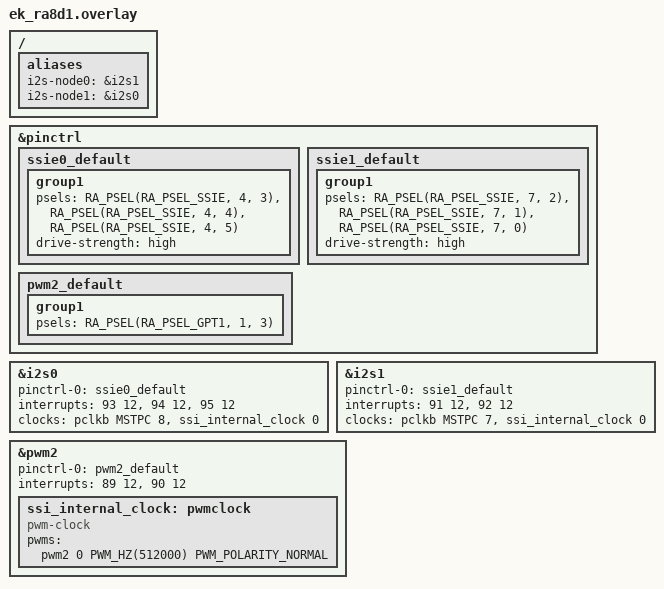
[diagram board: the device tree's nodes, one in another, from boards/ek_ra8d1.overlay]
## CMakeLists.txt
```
# SPDX-License-Identifier: Apache-2.0

cmake_minimum_required(VERSION 3.28.0)

find_package(Zephyr REQUIRED HINTS $ENV{ZEPHYR_BASE})
project(i2s_api)

FILE(GLOB app_sources src/*.c)
list(FILTER app_sources EXCLUDE REGEX "test_i2s_pm\\.c$")
target_sources(app PRIVATE ${app_sources})
target_sources_ifdef(CONFIG_PM app PRIVATE src/test_i2s_pm.c)
```

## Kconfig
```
#
# Copyright (c) 2021, NXP
#
# SPDX-License-Identifier: Apache-2.0
#

mainmenu "I2S Loopback Test"

source "Kconfig.zephyr"

config I2S_TEST_SEPARATE_DEVICES
	bool "Use two separate I2S ports for loopback"
	help
	  Use separate I2S ports for transmit and receive.

config I2S_TEST_USE_I2S_DIR_BOTH
	bool "Use I2S_DIR_BOTH value to perform RX/TX transfers"
	default y if DT_HAS_NORDIC_NRF_I2S_ENABLED || DT_HAS_NORDIC_NRF_TDM_ENABLED
	help
	  Use the I2S_DIR_BOTH enumeration value to trigger commands in test
	  cases involving both reception and transmission. Use of this option
	  is essential for devices that cannot independently start and stop
	  the RX and TX streams.

config I2S_TEST_USE_GPIO_LOOPBACK
	bool "Use GPIO loopback"
	default y if DT_HAS_NORDIC_NRF_I2S_ENABLED || DT_HAS_NORDIC_NRF_TDM_ENABLED
	help
	  Use wiring between the data-out and data-in pins for looping back
	  data. This option is intended to be used for devices that do not
	  provide the internal loopback functionality.

config I2S_TEST_ALLOWED_DATA_OFFSET
	int "Allowed offset in received data"
	default 2 if DT_HAS_NORDIC_NRF_I2S_ENABLED || DT_HAS_NORDIC_NRF_TDM_ENABLED
	default 0
	help
	  Maximum allowed offset between sent and received samples. Non-zero
	  value of this option may be needed when GPIO loopback is used.

config I2S_TEST_ALLOW_VARIABLE_OFFSET
	bool "Recalculate the data offset on every block read"
	help
	  If the data offset is not consistent between reads because of
	  timing variations in the hardware, enable this option to
	  always recalculate the offset.
```

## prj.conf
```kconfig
CONFIG_I2S=y
CONFIG_ZTEST=y
CONFIG_TEST_USERSPACE=y
# The tdm_channel_masking test suite may be skipped
CONFIG_ZTEST_VERIFY_RUN_ALL=n
```

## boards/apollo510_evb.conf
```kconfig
# Copyright (c) 2026 Ambiq Micro Inc.
# SPDX-License-Identifier: Apache-2.0

CONFIG_I2S_TEST_USE_GPIO_LOOPBACK=y
CONFIG_I2S_TEST_USE_I2S_DIR_BOTH=y
CONFIG_I2S_TEST_ALLOWED_DATA_OFFSET=2
```

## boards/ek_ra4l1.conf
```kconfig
# Copyright (c) 2025 Renesas Electronics Corporation
# SPDX-License-Identifier: Apache-2.0

CONFIG_I2S_INIT_PRIORITY=52
CONFIG_I2S_TEST_USE_GPIO_LOOPBACK=y
CONFIG_I2S_TEST_USE_I2S_DIR_BOTH=y
```

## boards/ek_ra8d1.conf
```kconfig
# Copyright (c) 2025 Renesas Electronics Corporation
# SPDX-License-Identifier: Apache-2.0

CONFIG_I2S_INIT_PRIORITY=52
CONFIG_I2S_TEST_USE_GPIO_LOOPBACK=y
CONFIG_I2S_TEST_SEPARATE_DEVICES=y
```

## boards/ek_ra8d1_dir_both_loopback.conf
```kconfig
#
# Copyright (c) 2025 Renesas Electronics Corporation
#
# SPDX-License-Identifier: Apache-2.0
#

CONFIG_PWM=y
CONFIG_CLOCK_CONTROL=y
CONFIG_I2S_INIT_PRIORITY=52
CONFIG_I2S_TEST_USE_GPIO_LOOPBACK=y
CONFIG_I2S_TEST_USE_I2S_DIR_BOTH=y
CONFIG_CLOCK_CONTROL_FIXED_RATE_CLOCK=y
```

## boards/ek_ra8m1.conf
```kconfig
#
# Copyright (c) 2025 Renesas Electronics Corporation
#
# SPDX-License-Identifier: Apache-2.0
#

CONFIG_PWM=y
CONFIG_CLOCK_CONTROL=y
CONFIG_I2S_INIT_PRIORITY=52
CONFIG_I2S_TEST_USE_GPIO_LOOPBACK=y
CONFIG_I2S_TEST_SEPARATE_DEVICES=y
CONFIG_CLOCK_CONTROL_FIXED_RATE_CLOCK=y
```

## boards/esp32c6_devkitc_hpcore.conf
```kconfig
# Copyright (c) 2025 Espressif Systems (Shanghai) Co., Ltd.
# SPDX-License-Identifier: Apache-2.0

CONFIG_I2S_TEST_USE_GPIO_LOOPBACK=y
CONFIG_I2S_TEST_ALLOWED_DATA_OFFSET=1
```

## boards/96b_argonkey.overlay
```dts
test_i2s_rx: &i2s5 {};

test_i2s_tx: &i2s5 {};
```

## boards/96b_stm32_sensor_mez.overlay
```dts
/*
 * SPDX-FileCopyrightText: Copyright The Zephyr Project Contributors
 * SPDX-License-Identifier: Apache-2.0
 */

/* i2s-node0 is the transmitter/receiver */

/ {
	aliases {
		i2s-node0 = &i2s2;
	};
};
```

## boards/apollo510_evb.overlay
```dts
/*
 * Copyright (c) 2026 Ambiq Micro Inc.
 *
 * SPDX-License-Identifier: Apache-2.0
 */

/*
 * GPIO loopback: wire I2S0_SDOUT (P6) to I2S0_SDIN (P4).
 * CLK is P5, WS is P7.
 */

/ {
	aliases {
		i2s-node0 = &i2s0;
	};
};

&i2s0 {
	status = "okay";
};
```

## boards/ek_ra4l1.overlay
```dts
/*
 * Copyright (c) 2025 Renesas Electronics Corporation
 *
 * SPDX-License-Identifier: Apache-2.0
 */

#include <zephyr/dt-bindings/pwm/pwm.h>

/ {
	aliases {
		i2s-node0 = &i2s0;
	};
};

&pinctrl {
	ssie0_default: ssie0_default {
		group1 {
			/* SSI_BCK SSI_LRCK SSI_TX SSI_RX */
			psels = <RA_PSEL(RA_PSEL_SSIE, 4, 3)>,
				<RA_PSEL(RA_PSEL_SSIE, 4, 4)>,
				<RA_PSEL(RA_PSEL_SSIE, 6, 8)>,
				<RA_PSEL(RA_PSEL_SSIE, 1, 15)>;
			drive-strength = "high";
		};
	};

	pwm2_default: pwm2_default {
		group1 {
			/* GTIOC2A */
			psels = <RA_PSEL(RA_PSEL_GPT1, 4, 7)>;
		};
	};
};

&i2s0 {
	pinctrl-0 = <&ssie0_default>;
	pinctrl-names = "default";
	interrupts = <61 12>, <62 12>, <63 12>;
	interrupt-names = "ssi_txi", "ssi_rxi", "ssi_if";
	clocks = <&pclkb MSTPC 8>, <&ssi_internal_clock 0>;
	clock-names = "pclk", "audio-clock";
	status = "okay";
};

&pwm2 {
	pinctrl-0 = <&pwm2_default>;
	pinctrl-names = "default";
	interrupts = <59 12>, <60 12>;
	interrupt-names = "gtioca", "overflow";
	status = "okay";

	ssi_internal_clock: pwmclock {
		compatible = "pwm-clock";
		#clock-cells = <1>;
		pwms = <&pwm2 0 PWM_HZ(512000) PWM_POLARITY_NORMAL>;
		status = "okay";
	};
};
```

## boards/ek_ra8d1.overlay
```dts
/*
 * Copyright (c) 2025 Renesas Electronics Corporation
 *
 * SPDX-License-Identifier: Apache-2.0
 */

#include <zephyr/dt-bindings/pwm/pwm.h>

/ {
	aliases {
		i2s-node0 = &i2s1;
		i2s-node1 = &i2s0;
	};
};

&pinctrl {
	ssie0_default: ssie0_default {
		group1 {
			/* SSI_BCK SSI_LRCK SSI_TX */
			psels = <RA_PSEL(RA_PSEL_SSIE, 4, 3)>,
				<RA_PSEL(RA_PSEL_SSIE, 4, 4)>,
				<RA_PSEL(RA_PSEL_SSIE, 4, 5)>;
			drive-strength = "high";
		};
	};

	ssie1_default: ssie1_default {
		group1 {
			/* SSI_BCK SSI_LRCK SSI_DATA */
			psels = <RA_PSEL(RA_PSEL_SSIE, 7, 2)>,
				<RA_PSEL(RA_PSEL_SSIE, 7, 1)>,
				<RA_PSEL(RA_PSEL_SSIE, 7, 0)>;
			drive-strength = "high";
		};
	};

	pwm2_default: pwm2_default {
		group1 {
			/* GTIOC2A */
			psels = <RA_PSEL(RA_PSEL_GPT1, 1, 3)>;
		};
	};
};

&i2s0 {
	pinctrl-0 = <&ssie0_default>;
	pinctrl-names = "default";
	interrupts = <93 12>, <94 12>, <95 12>;
	interrupt-names = "ssi_txi", "ssi_rxi", "ssi_if";
	clocks = <&pclkb MSTPC 8>, <&ssi_internal_clock 0>;
	clock-names = "pclk", "audio-clock";
	status = "okay";
};

&i2s1 {
	pinctrl-0 = <&ssie1_default>;
	pinctrl-names = "default";
	interrupts = <91 12>, <92 12>;
	interrupt-names = "ssi_rt", "ssi_if";
	clocks = <&pclkb MSTPC 7>, <&ssi_internal_clock 0>;
	clock-names = "pclk", "audio-clock";
	status = "okay";
};

&pwm2 {
	pinctrl-0 = <&pwm2_default>;
	pinctrl-names = "default";
	interrupts = <89 12>, <90 12>;
	interrupt-names = "gtioca", "overflow";
	status = "okay";

	ssi_internal_clock: pwmclock {
		compatible = "pwm-clock";
		#clock-cells = <1>;
		pwms = <&pwm2 0 PWM_HZ(512000) PWM_POLARITY_NORMAL>;
		status = "okay";
	};
};
```

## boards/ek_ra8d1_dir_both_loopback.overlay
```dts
/*
 * Copyright (c) 2025 Renesas Electronics Corporation
 *
 * SPDX-License-Identifier: Apache-2.0
 */

#include <zephyr/dt-bindings/pwm/pwm.h>

/ {
	aliases {
		i2s-node0 = &i2s0;
	};
};

&pinctrl {
	ssie0_default: ssie0_default {
		group1 {
			/* SSI_BCK SSI_LRCK SSI_TX SSI_RX */
			psels = <RA_PSEL(RA_PSEL_SSIE, 4, 3)>,
				<RA_PSEL(RA_PSEL_SSIE, 4, 4)>,
				<RA_PSEL(RA_PSEL_SSIE, 4, 5)>,
				<RA_PSEL(RA_PSEL_SSIE, 4, 6)>;
			drive-strength = "high";
		};
	};

	pwm2_default: pwm2_default {
		group1 {
			/* GTIOC2A */
			psels = <RA_PSEL(RA_PSEL_GPT1, 1, 3)>;
		};
	};
};

&i2s0 {
	pinctrl-0 = <&ssie0_default>;
	pinctrl-names = "default";
	interrupts = <93 12>, <94 12>, <95 12>;
	interrupt-names = "ssi_txi", "ssi_rxi", "ssi_if";
	clocks = <&pclkb MSTPC 8>, <&ssi_internal_clock 0>;
	clock-names = "pclk", "audio-clock";
	status = "okay";
};

&pwm2 {
	pinctrl-0 = <&pwm2_default>;
	pinctrl-names = "default";
	interrupts = <91 12>, <92 12>;
	interrupt-names = "gtioca", "overflow";
	status = "okay";

	ssi_internal_clock: pwmclock {
		compatible = "pwm-clock";
		#clock-cells = <1>;
		pwms = <&pwm2 0 PWM_HZ(512000) PWM_POLARITY_NORMAL>;
		status = "okay";
	};
};
```

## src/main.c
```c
/*
 * Copyright (c) 2017 comsuisse AG
 *
 * SPDX-License-Identifier: Apache-2.0
 */


#include <zephyr/kernel.h>
#include <zephyr/ztest.h>
#include <zephyr/device.h>
#include "i2s_api_test.h"

ZTEST_DMEM const struct device *dev_i2s_rx =
	DEVICE_DT_GET_OR_NULL(I2S_DEV_NODE_RX);
ZTEST_DMEM const struct device *dev_i2s_tx =
	DEVICE_DT_GET_OR_NULL(I2S_DEV_NODE_TX);
ZTEST_DMEM const struct device *dev_i2s =
	DEVICE_DT_GET_OR_NULL(I2S_DEV_NODE_RX);
ZTEST_DMEM bool dir_both_supported;

static void *setup(void)
{
	k_thread_access_grant(k_current_get(),
			      &rx_mem_slab, &tx_mem_slab);
	k_object_access_grant(dev_i2s_rx, k_current_get());
	k_object_access_grant(dev_i2s_tx, k_current_get());

	return NULL;
}

static void before(void *fixture)
{
	ARG_UNUSED(fixture);

	int ret;

	zassert_not_null(dev_i2s_rx, "RX device not found");
	zassert_true(device_is_ready(dev_i2s_rx),
		     "device %s is not ready", dev_i2s_rx->name);
	zassert_not_null(dev_i2s_tx, "TX device not found");
	zassert_true(device_is_ready(dev_i2s_tx),
		     "device %s is not ready", dev_i2s_tx->name);

	ret = configure_stream(dev_i2s_rx, I2S_DIR_RX);
	zassert_equal(ret, TC_PASS);

	ret = configure_stream(dev_i2s_tx, I2S_DIR_TX);
	zassert_equal(ret, TC_PASS);
}

static void before_dir_both(void *fixture)
{
	ARG_UNUSED(fixture);

	int ret;

	zassert_not_null(dev_i2s, "TX/RX device not found");
	zassert_true(device_is_ready(dev_i2s),
		     "device %s is not ready", dev_i2s->name);

	ret = configure_stream(dev_i2s, I2S_DIR_BOTH);
	zassert_equal(ret, TC_PASS);

	/* Check if the tested driver supports the I2S_DIR_BOTH value.
	 * Use the DROP trigger for this, as in the current state of the driver
	 * (READY, both TX and RX queues empty) it is actually a no-op.
	 */
	ret = i2s_trigger(dev_i2s, I2S_DIR_BOTH, I2S_TRIGGER_DROP);
	dir_both_supported = (ret == 0);

	if (IS_ENABLED(CONFIG_I2S_TEST_USE_I2S_DIR_BOTH)) {
		zassert_true(dir_both_supported,
			     "I2S_DIR_BOTH value is supposed to be supported.");
	}
}

ZTEST_SUITE(i2s_loopback, NULL, setup, before, NULL, NULL);
ZTEST_SUITE(i2s_states, NULL, setup, before, NULL, NULL);
ZTEST_SUITE(i2s_dir_both_states, NULL, setup, before_dir_both, NULL, NULL);
ZTEST_SUITE(i2s_dir_both_loopback, NULL, setup, before_dir_both, NULL, NULL);
ZTEST_SUITE(i2s_errors, NULL, setup, before, NULL, NULL);
ZTEST_SUITE(tdm_channel_masking, tdm_channel_masking_supported, setup, before_dir_both, NULL, NULL);
```

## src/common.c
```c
/*
 * Copyright (c) 2017 comsuisse AG
 *
 * SPDX-License-Identifier: Apache-2.0
 */

#include <zephyr/kernel.h>
#include <zephyr/ztest.h>
#include <zephyr/drivers/i2s.h>
#include "i2s_api_test.h"

/* Cache-line align the blocks so cache maintenance on one block cannot
 * corrupt a neighbouring block
 */
#ifdef CONFIG_DCACHE_LINE_SIZE
#define SLAB_ALIGN MAX(32, CONFIG_DCACHE_LINE_SIZE)
#else
#define SLAB_ALIGN 32
#endif

K_MEM_SLAB_DEFINE(rx_mem_slab, BLOCK_SIZE, NUM_RX_BLOCKS, SLAB_ALIGN);
K_MEM_SLAB_DEFINE(tx_mem_slab, BLOCK_SIZE, NUM_TX_BLOCKS, SLAB_ALIGN);

/* The data_l represent a sine wave */
ZTEST_DMEM int16_t data_l[SAMPLE_NO] = {
	  6392,  12539,  18204,  23169,  27244,  30272,  32137,  32767,  32137,
	 30272,  27244,  23169,  18204,  12539,   6392,      0,  -6393, -12540,
	-18205, -23170, -27245, -30273, -32138, -32767, -32138, -30273, -27245,
	-23170, -18205, -12540,  -6393,     -1,
};

/* The data_r represent a sine wave with double the frequency of data_l */
ZTEST_DMEM int16_t data_r[SAMPLE_NO] = {
	 12539,  23169,  30272,  32767,  30272,  23169,  12539,      0, -12540,
	-23170, -30273, -32767, -30273, -23170, -12540,     -1,  12539,  23169,
	 30272,  32767,  30272,  23169,  12539,      0, -12540, -23170, -30273,
	-32767, -30273, -23170, -12540,     -1,
};

static void fill_buf(int16_t *tx_block, int att)
{
	for (int i = 0; i < SAMPLE_NO; i++) {
		tx_block[2 * i] = data_l[i] >> att;
		tx_block[2 * i + 1] = data_r[i] >> att;
	}
}

static int verify_buf(int16_t *rx_block, int att)
{
	int sample_no = SAMPLE_NO;

#if (CONFIG_I2S_TEST_ALLOWED_DATA_OFFSET > 0)
#if (CONFIG_I2S_TEST_ALLOW_VARIABLE_OFFSET)
	int offset = -1;
#else
	static ZTEST_DMEM int offset = -1;
#endif

	if (offset < 0) {
		do {
			++offset;
			if (offset > CONFIG_I2S_TEST_ALLOWED_DATA_OFFSET) {
				TC_PRINT("Allowed data offset exceeded\n");
				return -TC_FAIL;
			}
		} while (rx_block[2 * offset] != data_l[0] >> att);

#if (!CONFIG_I2S_TEST_ALLOW_VARIABLE_OFFSET)
		TC_PRINT("Using data offset: %d\n", offset);
#endif
	}

	rx_block += 2 * offset;
	sample_no -= offset;
#endif

	for (int i = 0; i < sample_no; i++) {
		if (rx_block[2 * i] != data_l[i] >> att) {
			TC_PRINT("Error: att %d: data_l mismatch at position "
				 "%d, expected %d, actual %d\n",
				 att, i, data_l[i] >> att, rx_block[2 * i]);
			return -TC_FAIL;
		}
		if (rx_block[2 * i + 1] != data_r[i] >> att) {
			TC_PRINT("Error: att %d: data_r mismatch at position "
				 "%d, expected %d, actual %d\n",
				 att, i, data_r[i] >> att, rx_block[2 * i + 1]);
			return -TC_FAIL;
		}
	}

	return TC_PASS;
}

void fill_buf_const(int16_t *tx_block, int16_t val_l, int16_t val_r)
{
	for (int i = 0; i < SAMPLE_NO; i++) {
		tx_block[2 * i] = val_l;
		tx_block[2 * i + 1] = val_r;
	}
}

int verify_buf_const(int16_t *rx_block, int16_t val_l, int16_t val_r)
{
	int sample_no = SAMPLE_NO;

#if (CONFIG_I2S_TEST_ALLOWED_DATA_OFFSET > 0)
	static ZTEST_DMEM int offset = -1;

	if (offset < 0) {
		do {
			++offset;
			if (offset > CONFIG_I2S_TEST_ALLOWED_DATA_OFFSET) {
				TC_PRINT("Allowed data offset exceeded\n");
				return -TC_FAIL;
			}
		} while (rx_block[2 * offset] != val_l);
	}

	rx_block += 2 * offset;
	sample_no -= offset;
#endif

	for (int i = 0; i < sample_no; i++) {
		if (rx_block[2 * i] != val_l) {
			TC_PRINT("Error: data_l mismatch at position "
				 "%d, expected %d, actual %d\n",
				 i, val_l, rx_block[2 * i]);
			return -TC_FAIL;
		}
		if (rx_block[2 * i + 1] != val_r) {
			TC_PRINT("Error: data_r mismatch at position "
				 "%d, expected %d, actual %d\n",
				 i, val_r, rx_block[2 * i + 1]);
			return -TC_FAIL;
		}
	}

	return TC_PASS;
}

static int tx_block_write_slab(const struct device *dev_i2s, int att, int err,
			       struct k_mem_slab *slab)
{
	char tx_block[BLOCK_SIZE];
	int ret;

	fill_buf((uint16_t *)tx_block, att);
	ret = i2s_buf_write(dev_i2s, tx_block, BLOCK_SIZE);
	if (ret != err) {
		TC_PRINT("Error: i2s_write failed expected %d, actual %d\n",
			 err, ret);
		return -TC_FAIL;
	}

	return TC_PASS;
}

int tx_block_write(const struct device *dev_i2s, int att, int err)
{
	return tx_block_write_slab(dev_i2s, att, err, &tx_mem_slab);
}

static int rx_block_read_slab(const struct device *dev_i2s, int att,
			      struct k_mem_slab *slab)
{
	char rx_block[BLOCK_SIZE];
	size_t rx_size;
	int ret;

	ret = i2s_buf_read(dev_i2s, rx_block, &rx_size);
	if (ret < 0 || rx_size != BLOCK_SIZE) {
		TC_PRINT("Error: Read failed\n");
		return -TC_FAIL;
	}
	ret = verify_buf((uint16_t *)rx_block, att);
	if (ret < 0) {
		TC_PRINT("Error: Verify failed\n");
		return -TC_FAIL;
	}

	return TC_PASS;
}

int rx_block_read(const struct device *dev_i2s, int att)
{
	return rx_block_read_slab(dev_i2s, att, &rx_mem_slab);
}

int configure_stream(const struct device *dev_i2s, enum i2s_dir dir)
{
	int ret;
	struct i2s_config i2s_cfg = {0};

	i2s_cfg.word_size = 16U;
	i2s_cfg.channels = 2U;
	i2s_cfg.format = I2S_FMT_DATA_FORMAT_I2S;
	i2s_cfg.frame_clk_freq = FRAME_CLK_FREQ;
	i2s_cfg.block_size = BLOCK_SIZE;
	i2s_cfg.timeout = TIMEOUT;

	if (dir == I2S_DIR_TX) {
		/* Configure the Transmit port as Controller */
		i2s_cfg.options = I2S_OPT_FRAME_CLK_CONTROLLER
				| I2S_OPT_BIT_CLK_CONTROLLER;
	} else if (dir == I2S_DIR_RX) {
		/* Configure the Receive port as Target */
		i2s_cfg.options = I2S_OPT_FRAME_CLK_TARGET
				| I2S_OPT_BIT_CLK_TARGET;
	} else { /* dir == I2S_DIR_BOTH */
		i2s_cfg.options = I2S_OPT_FRAME_CLK_CONTROLLER
				| I2S_OPT_BIT_CLK_CONTROLLER;
	}

	if (!IS_ENABLED(CONFIG_I2S_TEST_USE_GPIO_LOOPBACK)) {
		i2s_cfg.options |= I2S_OPT_LOOPBACK;
	}

	if (dir == I2S_DIR_TX || dir == I2S_DIR_BOTH) {
		i2s_cfg.mem_slab = &tx_mem_slab;
		ret = i2s_configure(dev_i2s, I2S_DIR_TX, &i2s_cfg);
		if (ret < 0) {
			TC_PRINT("Failed to configure I2S TX stream (%d)\n",
				 ret);
			return -TC_FAIL;
		}
	}

	if (dir == I2S_DIR_RX || dir == I2S_DIR_BOTH) {
		i2s_cfg.mem_slab = &rx_mem_slab;
		ret = i2s_configure(dev_i2s, I2S_DIR_RX, &i2s_cfg);
		if (ret < 0) {
			TC_PRINT("Failed to configure I2S RX stream (%d)\n",
				 ret);
			return -TC_FAIL;
		}
	}

	return TC_PASS;
}

int i2s_check_state(const struct device *dev_i2s, enum i2s_dir dir, enum i2s_state expected_state,
		    k_timeout_t timeout)
{
	k_timepoint_t end = sys_timepoint_calc(timeout);
	enum i2s_state state;

	do {
		state = i2s_get_state(dev_i2s, dir);

		if (state == expected_state) {
			return TC_PASS;
		}

		if ((state == I2S_STATE_UNKNOWN) && !I2S_TEST_STATE_REQUIRED) {
			TC_PRINT("State check skipped: driver does not report state for dir %d\n",
				 dir);
			return TC_PASS;
		}

		if (state != I2S_STATE_STOPPING) {
			break;
		}

		k_sleep(K_MSEC(1));
	} while (!sys_timepoint_expired(end));

	TC_PRINT("Unexpected state for dir %d: got %d, expected %d\n", dir, state, expected_state);

	return -TC_FAIL;
}
```

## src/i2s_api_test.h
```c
/*
 * Copyright (c) 2017 comsuisse AG
 * Copyright (c) 2018 Intel Corporation
 *
 * SPDX-License-Identifier: Apache-2.0
 */

#ifndef I2S_API_TEST_H
#define I2S_API_TEST_H

#include <zephyr/kernel.h>
#include <zephyr/drivers/i2s.h>

extern struct k_mem_slab rx_mem_slab;
extern struct k_mem_slab tx_mem_slab;

#define SAMPLE_NO	32
#define TIMEOUT		2000
#define FRAME_CLK_FREQ	8000

extern int16_t data_l[SAMPLE_NO];
extern int16_t data_r[SAMPLE_NO];

extern const struct device *dev_i2s_rx;
extern const struct device *dev_i2s_tx;
extern const struct device *dev_i2s;
extern bool dir_both_supported;

#define I2S_DEV_NODE_RX DT_ALIAS(i2s_node0)
#ifdef CONFIG_I2S_TEST_SEPARATE_DEVICES
#define I2S_DEV_NODE_TX DT_ALIAS(i2s_node1)
#else
#define I2S_DEV_NODE_TX DT_ALIAS(i2s_node0)
#endif
#define BLOCK_SIZE (2 * sizeof(data_l))

#define NUM_RX_BLOCKS	4
#define NUM_TX_BLOCKS	4

#define I2S_STATE_TIMEOUT K_MSEC(50)

/* Drivers known to implement i2s_get_state(). For these, I2S_STATE_UNKNOWN is
 * a test failure instead of a skipped check.
 */
#define I2S_TEST_STATE_REQUIRED DT_HAS_COMPAT_STATUS_OKAY(zephyr_native_sim_i2s)

int tx_block_write(const struct device *dev_i2s, int att, int err);
int rx_block_read(const struct device *dev_i2s, int att);

void fill_buf_const(int16_t *tx_block, int16_t val_l, int16_t val_r);
int verify_buf_const(int16_t *rx_block, int16_t val_l, int16_t val_r);

int configure_stream(const struct device *dev_i2s, enum i2s_dir dir);

int i2s_check_state(const struct device *dev_i2s, enum i2s_dir dir, enum i2s_state expected_state,
		    k_timeout_t timeout);

#endif
```

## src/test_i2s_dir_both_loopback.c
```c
/*
 * Copyright (c) 2017 comsuisse AG
 * Copyright (c) 2021 Nordic Semiconductor ASA
 *
 * SPDX-License-Identifier: Apache-2.0
 */

#include <zephyr/kernel.h>
#include <zephyr/ztest.h>
#include <zephyr/drivers/i2s.h>
#include "i2s_api_test.h"

/* The test cases here are copied from test_i2s_loopback.c and adapted for use
 * on devices that cannot independently start and stop the RX and TX streams
 * and require the use of the I2S_DIR_BOTH value for RX/TX transfers.
 */

/** @brief Short I2S transfer.
 *
 * - START trigger starts both the transmission and reception.
 * - Sending / receiving a short sequence of data returns success.
 * - DRAIN trigger empties the transmit queue and stops both streams.
 */
ZTEST_USER(i2s_dir_both_loopback, test_i2s_dir_both_transfer_short)
{
	if (!dir_both_supported) {
		TC_PRINT("I2S_DIR_BOTH value is not supported.\n");
		ztest_test_skip();
		return;
	}

	int ret;

	/* Prefill TX queue */
	ret = tx_block_write(dev_i2s, 0, 0);
	zassert_equal(ret, TC_PASS);
	TC_PRINT("%d->OK\n", 1);

	ret = tx_block_write(dev_i2s, 1, 0);
	zassert_equal(ret, TC_PASS);
	TC_PRINT("%d->OK\n", 2);

	ret = i2s_trigger(dev_i2s, I2S_DIR_BOTH, I2S_TRIGGER_START);
	zassert_equal(ret, 0, "RX/TX START trigger failed\n");

	ret = rx_block_read(dev_i2s, 0);
	zassert_equal(ret, TC_PASS);
	TC_PRINT("%d<-OK\n", 1);

	ret = tx_block_write(dev_i2s, 2, 0);
	zassert_equal(ret, TC_PASS);
	TC_PRINT("%d->OK\n", 3);

	/* All data written, drain TX queue and stop both streams. */
	ret = i2s_trigger(dev_i2s, I2S_DIR_BOTH, I2S_TRIGGER_DRAIN);
	zassert_equal(ret, 0, "RX/TX DRAIN trigger failed");

	ret = rx_block_read(dev_i2s, 1);
	zassert_equal(ret, TC_PASS);
	TC_PRINT("%d<-OK\n", 2);

	ret = rx_block_read(dev_i2s, 2);
	zassert_equal(ret, TC_PASS);
	TC_PRINT("%d<-OK\n", 3);

	ret = i2s_check_state(dev_i2s, I2S_DIR_TX, I2S_STATE_READY, I2S_STATE_TIMEOUT);
	zassert_equal(ret, TC_PASS);

	ret = i2s_check_state(dev_i2s, I2S_DIR_RX, I2S_STATE_READY, I2S_STATE_TIMEOUT);
	zassert_equal(ret, TC_PASS);
}

#define TEST_I2S_TRANSFER_LONG_REPEAT_COUNT  100

/** @brief Long I2S transfer.
 *
 * - START trigger starts both the transmission and reception.
 * - Sending / receiving a long sequence of data returns success.
 * - DRAIN trigger empties the transmit queue and stops both streams.
 */
ZTEST_USER(i2s_dir_both_loopback, test_i2s_dir_both_transfer_long)
{
	if (!dir_both_supported) {
		TC_PRINT("I2S_DIR_BOTH value is not supported.\n");
		ztest_test_skip();
		return;
	}

	int ret;

	/* Prefill TX queue */
	ret = tx_block_write(dev_i2s, 0, 0);
	zassert_equal(ret, TC_PASS);

	ret = i2s_trigger(dev_i2s, I2S_DIR_BOTH, I2S_TRIGGER_START);
	zassert_equal(ret, 0, "RX/TX START trigger failed\n");

	for (int i = 0; i < TEST_I2S_TRANSFER_LONG_REPEAT_COUNT; i++) {
		ret = tx_block_write(dev_i2s, 0, 0);
		zassert_equal(ret, TC_PASS);

		ret = rx_block_read(dev_i2s, 0);
		zassert_equal(ret, TC_PASS);
	}

	/* All data written, all but one data block read, flush TX queue
	 * and stop both streams.
	 */
	ret = i2s_trigger(dev_i2s, I2S_DIR_BOTH, I2S_TRIGGER_DRAIN);
	zassert_equal(ret, 0, "RX/TX DRAIN trigger failed");

	ret = rx_block_read(dev_i2s, 0);
	zassert_equal(ret, TC_PASS);

	ret = i2s_check_state(dev_i2s, I2S_DIR_TX, I2S_STATE_READY, I2S_STATE_TIMEOUT);
	zassert_equal(ret, TC_PASS);

	ret = i2s_check_state(dev_i2s, I2S_DIR_RX, I2S_STATE_READY, I2S_STATE_TIMEOUT);
	zassert_equal(ret, TC_PASS);
}

/** @brief Re-start I2S transfer.
 *
 * - STOP trigger stops transfer / reception at the end of the current block,
 *   consecutive START trigger restarts transfer / reception with the next data
 *   block.
 */
ZTEST_USER(i2s_dir_both_loopback, test_i2s_dir_both_transfer_restart)
{
	if (!dir_both_supported) {
		TC_PRINT("I2S_DIR_BOTH value is not supported.\n");
		ztest_test_skip();
		return;
	}

	int ret;

	/* Prefill TX queue */
	ret = tx_block_write(dev_i2s, 0, 0);
	zassert_equal(ret, TC_PASS);
	TC_PRINT("%d->OK\n", 1);

	ret = tx_block_write(dev_i2s, 1, 0);
	zassert_equal(ret, TC_PASS);
	TC_PRINT("%d->OK\n", 2);

	ret = i2s_trigger(dev_i2s, I2S_DIR_BOTH, I2S_TRIGGER_START);
	zassert_equal(ret, 0, "RX/TX START trigger failed\n");

	ret = i2s_trigger(dev_i2s, I2S_DIR_BOTH, I2S_TRIGGER_STOP);
	zassert_equal(ret, 0, "RX/TX STOP trigger failed");

	ret = rx_block_read(dev_i2s, 0);
	zassert_equal(ret, TC_PASS);
	TC_PRINT("%d<-OK\n", 1);

	TC_PRINT("Stop transmission\n");

	/* Keep interface inactive */
	k_sleep(K_MSEC(1000));

	TC_PRINT("Start transmission\n");

	/* Prefill TX queue */
	ret = tx_block_write(dev_i2s, 2, 0);
	zassert_equal(ret, TC_PASS);
	TC_PRINT("%d->OK\n", 3);

	ret = i2s_trigger(dev_i2s, I2S_DIR_BOTH, I2S_TRIGGER_START);
	zassert_equal(ret, 0, "RX/TX START trigger failed\n");

	ret = i2s_trigger(dev_i2s, I2S_DIR_BOTH, I2S_TRIGGER_DRAIN);
	zassert_equal(ret, 0, "RX/TX DRAIN trigger failed");

	ret = rx_block_read(dev_i2s, 1);
	zassert_equal(ret, TC_PASS);
	TC_PRINT("%d<-OK\n", 2);

	ret = rx_block_read(dev_i2s, 2);
	zassert_equal(ret, TC_PASS);
	TC_PRINT("%d<-OK\n", 3);
}

/** @brief RX buffer overrun.
 *
 * - In case of RX buffer overrun it is possible to read out RX data blocks
 *   that are stored in the RX queue.
 * - Reading from an empty RX queue when the RX buffer overrun occurred results
 *   in an error.
 * - Sending PREPARE trigger after the RX buffer overrun occurred changes
 *   the interface state to READY.
 */
ZTEST_USER(i2s_dir_both_loopback, test_i2s_dir_both_transfer_rx_overrun)
{
	if (!dir_both_supported) {
		TC_PRINT("I2S_DIR_BOTH value is not supported.\n");
		ztest_test_skip();
		return;
	}

	size_t rx_size;
	int ret;
	char rx_buf[BLOCK_SIZE];

	/* Prefill TX queue */
	ret = tx_block_write(dev_i2s, 0, 0);
	zassert_equal(ret, TC_PASS);

	ret = i2s_trigger(dev_i2s, I2S_DIR_BOTH, I2S_TRIGGER_START);
	zassert_equal(ret, 0, "RX/TX START trigger failed\n");

	for (int i = 0; i < NUM_RX_BLOCKS; i++) {
		ret = tx_block_write(dev_i2s, 0, 0);
		zassert_equal(ret, TC_PASS);
	}

	/* All data written, flush TX queue and stop the transmission */
	ret = i2s_trigger(dev_i2s, I2S_DIR_BOTH, I2S_TRIGGER_DRAIN);
	zassert_equal(ret, 0, "RX/TX DRAIN trigger failed");

	/* Wait for transmission to finish */
	k_sleep(K_MSEC(200));

	/* Read one data block, expect success even if RX queue is already in
	 * the error state.
	 */
	ret = rx_block_read(dev_i2s, 0);
	zassert_equal(ret, TC_PASS);

	/* Attempt to read more data blocks than are available in the RX queue */
	for (int i = 0; i < NUM_RX_BLOCKS; i++) {
		ret = i2s_buf_read(dev_i2s, rx_buf, &rx_size);
		if (ret != 0) {
			break;
		}
	}
	zassert_equal(ret, -EIO, "RX overrun error not detected");

	ret = i2s_trigger(dev_i2s, I2S_DIR_RX, I2S_TRIGGER_PREPARE);
	zassert_equal(ret, 0, "RX PREPARE trigger failed");

	/* Transmit and receive one more data block */
	ret = tx_block_write(dev_i2s, 0, 0);
	zassert_equal(ret, TC_PASS);
	ret = i2s_trigger(dev_i2s, I2S_DIR_BOTH, I2S_TRIGGER_START);
	zassert_equal(ret, 0, "RX/TX START trigger failed\n");
	ret = i2s_trigger(dev_i2s, I2S_DIR_BOTH, I2S_TRIGGER_DRAIN);
	zassert_equal(ret, 0, "RX/TX DRAIN trigger failed");
	ret = rx_block_read(dev_i2s, 0);
	zassert_equal(ret, TC_PASS);

	k_sleep(K_MSEC(200));
}

/** @brief TX buffer underrun.
 *
 * - An attempt to write to the TX queue when TX buffer underrun has occurred
 *   results in an error.
 * - Sending PREPARE trigger after the TX buffer underrun occurred changes
 *   the interface state to READY.
 */
ZTEST_USER(i2s_dir_both_loopback, test_i2s_dir_both_transfer_tx_underrun)
{
	if (!dir_both_supported) {
		TC_PRINT("I2S_DIR_BOTH value is not supported.\n");
		ztest_test_skip();
		return;
	}

	int ret;

	/* Prefill TX queue */
	ret = tx_block_write(dev_i2s, 0, 0);
	zassert_equal(ret, TC_PASS);

	ret = i2s_trigger(dev_i2s, I2S_DIR_BOTH, I2S_TRIGGER_START);
	zassert_equal(ret, 0, "RX/TX START trigger failed\n");

	ret = rx_block_read(dev_i2s, 0);
	zassert_equal(ret, TC_PASS);

	k_sleep(K_MSEC(200));

	/* Write one more TX data block, expect an error */
	ret = tx_block_write(dev_i2s, 2, -EIO);
	zassert_equal(ret, TC_PASS);

	ret = i2s_trigger(dev_i2s, I2S_DIR_BOTH, I2S_TRIGGER_PREPARE);
	zassert_equal(ret, 0, "RX/TX PREPARE trigger failed");

	k_sleep(K_MSEC(200));

	/* Transmit and receive two more data blocks */
	ret = tx_block_write(dev_i2s, 1, 0);
	zassert_equal(ret, TC_PASS);
	ret = tx_block_write(dev_i2s, 1, 0);
	zassert_equal(ret, TC_PASS);
	ret = i2s_trigger(dev_i2s, I2S_DIR_BOTH, I2S_TRIGGER_START);
	zassert_equal(ret, 0, "RX/TX START trigger failed\n");
	ret = rx_block_read(dev_i2s, 1);
	zassert_equal(ret, TC_PASS);
	ret = i2s_trigger(dev_i2s, I2S_DIR_BOTH, I2S_TRIGGER_DRAIN);
	zassert_equal(ret, 0, "RX/TX DRAIN trigger failed");
	ret = rx_block_read(dev_i2s, 1);
	zassert_equal(ret, TC_PASS);

	k_sleep(K_MSEC(200));
}

#define TEST_I2S_RECOVERY_REPEAT_COUNT 5

/** @brief TX underrun error with immediate single-direction PREPARE(TX) recovery.
 *
 * - An active I2S_DIR_BOTH transfer encounters a TX underrun error.
 * - Immediately recover using single-direction PREPARE(TX) without draining.
 * - Immediately restart the prepared direction (TX).
 * - Repeat across multiple iterations to verify clean recovery and buffer reuse.
 */
ZTEST_USER(i2s_dir_both_loopback, test_i2s_dir_both_tx_underrun_immediate_prepare_tx)
{
	if (!dir_both_supported) {
		TC_PRINT("I2S_DIR_BOTH value is not supported.\n");
		ztest_test_skip();
		return;
	}

	int ret;

	for (int iter = 0; iter < TEST_I2S_RECOVERY_REPEAT_COUNT; iter++) {
		/* Prefill only one TX block so underrun occurs promptly */
		ret = tx_block_write(dev_i2s, 0, 0);
		zassert_equal(ret, TC_PASS);

		ret = i2s_trigger(dev_i2s, I2S_DIR_BOTH, I2S_TRIGGER_START);
		zassert_equal(ret, 0, "RX/TX START trigger failed");

		/* Read the one data block */
		ret = rx_block_read(dev_i2s, 0);
		zassert_equal(ret, TC_PASS);

		/* Wait for underrun to occur */
		k_sleep(K_MSEC(200));

		/* Write should now fail with -EIO due to underrun error state */
		ret = tx_block_write(dev_i2s, 2, -EIO);
		zassert_equal(ret, TC_PASS);

		/* Issue single-direction PREPARE(TX) while active_dir
		 * is still I2S_DIR_BOTH.
		 */
		ret = i2s_trigger(dev_i2s, I2S_DIR_TX, I2S_TRIGGER_PREPARE);
		zassert_equal(ret, 0, "PREPARE trigger failed");

		/* Immediately write TX blocks and restart the prepared direction (TX) */
		ret = tx_block_write(dev_i2s, 1, 0);
		zassert_equal(ret, TC_PASS);
		ret = tx_block_write(dev_i2s, 1, 0);
		zassert_equal(ret, TC_PASS);

		ret = i2s_trigger(dev_i2s, I2S_DIR_TX, I2S_TRIGGER_START);
		zassert_equal(ret, 0, "TX START restart failed");

		ret = i2s_trigger(dev_i2s, I2S_DIR_TX, I2S_TRIGGER_DRAIN);
		zassert_equal(ret, 0, "TX DRAIN trigger failed");

		/* Wait for TX to finish draining completely before touching the peer */
		k_sleep(K_MSEC(200));

		/* Quiesce peer stream before the next iteration */
		ret = i2s_trigger(dev_i2s, I2S_DIR_RX, I2S_TRIGGER_DROP);
		zassert_equal(ret, 0, "RX DROP trigger failed");
	}
}
```

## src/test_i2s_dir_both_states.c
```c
/*
 * Copyright (c) 2017 comsuisse AG
 * Copyright (c) 2021 Nordic Semiconductor ASA
 *
 * SPDX-License-Identifier: Apache-2.0
 */

#include <zephyr/kernel.h>
#include <zephyr/ztest.h>
#include <zephyr/drivers/i2s.h>
#include "i2s_api_test.h"

/* The test cases here are copied from test_i2s_states.c and adapted for use
 * on devices that cannot independently start and stop the RX and TX streams
 * and require the use of the I2S_DIR_BOTH value for RX/TX transfers.
 */

#define TEST_I2S_STATE_RUNNING_NEG_REPEAT_COUNT  5

/** @brief Verify all failure cases in RUNNING state.
 *
 * - Sending START, PREPARE trigger in RUNNING state returns failure.
 */
ZTEST_USER(i2s_dir_both_states, test_i2s_dir_both_state_running_neg)
{
	if (!dir_both_supported) {
		TC_PRINT("I2S_DIR_BOTH value is not supported.\n");
		ztest_test_skip();
		return;
	}

	int ret;

	/* Prefill TX queue */
	ret = tx_block_write(dev_i2s, 0, 0);
	zassert_equal(ret, TC_PASS);

	ret = i2s_trigger(dev_i2s, I2S_DIR_BOTH, I2S_TRIGGER_START);
	zassert_equal(ret, 0, "RX/TX START trigger failed\n");

	for (int i = 0; i < TEST_I2S_STATE_RUNNING_NEG_REPEAT_COUNT; i++) {
		ret = tx_block_write(dev_i2s, 0, 0);
		zassert_equal(ret, TC_PASS);

		ret = rx_block_read(dev_i2s, 0);
		zassert_equal(ret, TC_PASS);

		/* Send invalid triggers, expect failure */
		ret = i2s_trigger(dev_i2s, I2S_DIR_BOTH, I2S_TRIGGER_START);
		zassert_equal(ret, -EIO);
		ret = i2s_trigger(dev_i2s, I2S_DIR_BOTH, I2S_TRIGGER_PREPARE);
		zassert_equal(ret, -EIO);
	}

	/* All data written, drain TX queue and stop both streams. */
	ret = i2s_trigger(dev_i2s, I2S_DIR_BOTH, I2S_TRIGGER_DRAIN);
	zassert_equal(ret, 0, "RX/TX DRAIN trigger failed");

	ret = rx_block_read(dev_i2s, 0);
	zassert_equal(ret, TC_PASS);
}

/** @brief Verify all failure cases in STOPPING state.
 *
 * - Sending START, STOP, DRAIN, PREPARE trigger in STOPPING state returns
 *   failure.
 */
ZTEST_USER(i2s_dir_both_states, test_i2s_dir_both_state_stopping_neg)
{
	if (!dir_both_supported) {
		TC_PRINT("I2S_DIR_BOTH value is not supported.\n");
		ztest_test_skip();
		return;
	}

	int ret;

	/* Prefill TX queue */
	ret = tx_block_write(dev_i2s, 0, 0);
	zassert_equal(ret, TC_PASS);

	ret = i2s_trigger(dev_i2s, I2S_DIR_BOTH, I2S_TRIGGER_START);
	zassert_equal(ret, 0, "RX/TX START trigger failed\n");

	ret = tx_block_write(dev_i2s, 0, 0);
	zassert_equal(ret, TC_PASS);

	ret = rx_block_read(dev_i2s, 0);
	zassert_equal(ret, TC_PASS);

	/* All data written, all but one data block read, flush TX queue and
	 * stop both streams.
	 */
	ret = i2s_trigger(dev_i2s, I2S_DIR_BOTH, I2S_TRIGGER_DRAIN);
	zassert_equal(ret, 0, "RX/TX DRAIN trigger failed");

	/* Send invalid triggers, expect failure */
	ret = i2s_trigger(dev_i2s, I2S_DIR_BOTH, I2S_TRIGGER_START);
	zassert_equal(ret, -EIO);
	ret = i2s_trigger(dev_i2s, I2S_DIR_BOTH, I2S_TRIGGER_STOP);
	zassert_equal(ret, -EIO);
	ret = i2s_trigger(dev_i2s, I2S_DIR_BOTH, I2S_TRIGGER_DRAIN);
	zassert_equal(ret, -EIO);
	ret = i2s_trigger(dev_i2s, I2S_DIR_BOTH, I2S_TRIGGER_PREPARE);
	zassert_equal(ret, -EIO);

	ret = rx_block_read(dev_i2s, 0);
	zassert_equal(ret, TC_PASS);

	/* This is in case the RX channel is stuck in STOPPING state.
	 * Clear out the state before running the next test.
	 */
	ret = i2s_trigger(dev_i2s, I2S_DIR_BOTH, I2S_TRIGGER_DROP);
	zassert_equal(ret, 0, "RX/TX DROP trigger failed");
}

/** @brief Verify all failure cases in ERROR state.
 *
 * - Sending START, STOP, DRAIN trigger in ERROR state returns failure.
 */
ZTEST_USER(i2s_dir_both_states, test_i2s_dir_both_state_error_neg)
{
	if (!dir_both_supported) {
		TC_PRINT("I2S_DIR_BOTH value is not supported.\n");
		ztest_test_skip();
		return;
	}

	size_t rx_size;
	int ret;
	char rx_buf[BLOCK_SIZE];

	/* Prefill TX queue */
	ret = tx_block_write(dev_i2s, 0, 0);
	zassert_equal(ret, TC_PASS);

	ret = i2s_trigger(dev_i2s, I2S_DIR_BOTH, I2S_TRIGGER_START);
	zassert_equal(ret, 0, "RX/TX START trigger failed\n");

	for (int i = 0; i < NUM_RX_BLOCKS; i++) {
		ret = tx_block_write(dev_i2s, 0, 0);
		zassert_equal(ret, TC_PASS);
	}

	/* Wait for transmission to finish */
	k_sleep(K_MSEC(200));

	/* Read one data block, expect success even if RX queue is already in
	 * the error state.
	 */
	ret = rx_block_read(dev_i2s, 0);
	zassert_equal(ret, TC_PASS);

	/* Attempt to read more data blocks than are available in the RX queue */
	for (int i = 0; i < NUM_RX_BLOCKS; i++) {
		ret = i2s_buf_read(dev_i2s, rx_buf, &rx_size);
		if (ret != 0) {
			break;
		}
	}
	zassert_equal(ret, -EIO, "RX overrun error not detected");

	/* Write one more TX data block, expect an error */
	ret = tx_block_write(dev_i2s, 2, -EIO);
	zassert_equal(ret, TC_PASS);

	/* Send invalid triggers, expect failure */
	ret = i2s_trigger(dev_i2s, I2S_DIR_BOTH, I2S_TRIGGER_START);
	zassert_equal(ret, -EIO);
	ret = i2s_trigger(dev_i2s, I2S_DIR_BOTH, I2S_TRIGGER_STOP);
	zassert_equal(ret, -EIO);
	ret = i2s_trigger(dev_i2s, I2S_DIR_BOTH, I2S_TRIGGER_DRAIN);
	zassert_equal(ret, -EIO);

	/* Recover from ERROR state */
	ret = i2s_trigger(dev_i2s, I2S_DIR_BOTH, I2S_TRIGGER_PREPARE);
	zassert_equal(ret, 0, "RX/TX PREPARE trigger failed");

	/* Transmit and receive one more data block */
	ret = tx_block_write(dev_i2s, 0, 0);
	zassert_equal(ret, TC_PASS);
	ret = i2s_trigger(dev_i2s, I2S_DIR_BOTH, I2S_TRIGGER_START);
	zassert_equal(ret, 0, "RX/TX START trigger failed");
	ret = i2s_trigger(dev_i2s, I2S_DIR_BOTH, I2S_TRIGGER_DRAIN);
	zassert_equal(ret, 0, "RX/TX DRAIN trigger failed");
	ret = rx_block_read(dev_i2s, 0);
	zassert_equal(ret, TC_PASS);

	k_sleep(K_MSEC(200));
}
```

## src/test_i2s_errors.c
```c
/*
 * Copyright (c) 2024 Nordic Semiconductor ASA
 *
 * SPDX-License-Identifier: Apache-2.0
 */

#include <zephyr/kernel.h>
#include <zephyr/ztest.h>
#include <zephyr/audio/audio_caps.h>
#include <zephyr/drivers/i2s.h>

#include "i2s_api_test.h"

#define INVALID_TRIGGER_SETTING 7

ZTEST_USER(i2s_errors, test_i2s_improper_configuration)
{
	int err;
	struct i2s_config invalid_config = { .word_size = 16U,
					     .channels = 2U,
					     .format = I2S_FMT_DATA_FORMAT_I2S,
					     .frame_clk_freq = FRAME_CLK_FREQ,
					     .block_size = BLOCK_SIZE,
					     .timeout = TIMEOUT,
					     .options = I2S_OPT_FRAME_CLK_CONTROLLER |
							I2S_OPT_BIT_CLK_CONTROLLER,
					     .mem_slab = &tx_mem_slab };


	invalid_config.format =
		I2S_FMT_DATA_FORMAT_LEFT_JUSTIFIED | I2S_FMT_DATA_FORMAT_RIGHT_JUSTIFIED;

	err = i2s_configure(dev_i2s, I2S_DIR_TX, &invalid_config);
	zassert_not_equal(
		err, 0,
		"I2S configuration did not detect improper data format (I2S_FMT_DATA_FORMAT_LEFT_JUSTIFIED | I2S_FMT_DATA_FORMAT_RIGHT_JUSTIFIED)");

	invalid_config.format = I2S_FMT_DATA_FORMAT_I2S | I2S_FMT_DATA_ORDER_LSB;

	err = i2s_configure(dev_i2s, I2S_DIR_TX, &invalid_config);
	zassert_not_equal(
		err, 0,
		"I2S configuration did not detect improper stream format (I2S_FMT_DATA_ORDER_LSB)");

	invalid_config.format = I2S_FMT_DATA_FORMAT_I2S;
	invalid_config.channels = 3U;
	err = i2s_configure(dev_i2s, I2S_DIR_TX, &invalid_config);
	zassert_not_equal(err, 0,
			  "I2S configuration did not detect improper channels configuration (3)");
}

ZTEST_USER(i2s_errors, test_i2s_config_attempt_in_wrong_state)
{
	int err;
	int config_err;
	char tx_data[BLOCK_SIZE] = {0};
	struct i2s_config inactive_config = { .word_size = 16U,
					      .channels = 2U,
					      .format = I2S_FMT_DATA_FORMAT_I2S,
					      .frame_clk_freq = FRAME_CLK_FREQ,
					      .block_size = BLOCK_SIZE,
					      .timeout = TIMEOUT,
					      .options = I2S_OPT_FRAME_CLK_CONTROLLER |
							 I2S_OPT_BIT_CLK_CONTROLLER,
					      .mem_slab = &tx_mem_slab };

	err = i2s_configure(dev_i2s, I2S_DIR_TX, &inactive_config);
	zassert_equal(err, 0, "I2S interface configuration failed, err=%d", err);

	err = i2s_buf_write(dev_i2s, tx_data, BLOCK_SIZE);
	zassert_equal(err, 0, "I2S buffer write unexpected error: %d", err);

	err = i2s_trigger(dev_i2s, I2S_DIR_TX, I2S_TRIGGER_START);
	zassert_equal(err, 0, "I2S_TRIGGER_START unexpected error: %d", err);

	config_err = i2s_configure(dev_i2s, I2S_DIR_TX, &inactive_config);

	err = i2s_trigger(dev_i2s, I2S_DIR_TX, I2S_TRIGGER_STOP);
	zassert_equal(err, 0, "I2S_TRIGGER_STOP unexpected error: %d", err);

	err = i2s_trigger(dev_i2s, I2S_DIR_TX, I2S_TRIGGER_DROP);
	zassert_equal(err, 0, "I2S_TRIGGER_DROP unexpected error: %d", err);

	zassert_not_equal(
		config_err, 0,
		"I2S configuration should not be possible in states other than I2S_STATE_READY");
}

ZTEST_USER(i2s_errors, test_i2s_incorrect_trigger)
{
	int err;
	char tx_data[BLOCK_SIZE] = {0};
	struct i2s_config test_config = { .word_size = 16U,
					  .channels = 2U,
					  .format = I2S_FMT_DATA_FORMAT_I2S,
					  .frame_clk_freq = FRAME_CLK_FREQ,
					  .block_size = BLOCK_SIZE,
					  .timeout = TIMEOUT,
					  .options = I2S_OPT_FRAME_CLK_CONTROLLER |
						     I2S_OPT_BIT_CLK_CONTROLLER,
					  .mem_slab = &tx_mem_slab };

	err = i2s_configure(dev_i2s, I2S_DIR_TX, &test_config);
	zassert_equal(err, 0, "CFG err=%d", err);

	err = i2s_buf_write(dev_i2s, tx_data, BLOCK_SIZE);
	zassert_equal(err, 0, "I2S buffer write unexpected error: %d", err);

	err = i2s_trigger(dev_i2s, I2S_DIR_TX, INVALID_TRIGGER_SETTING);
	zassert_equal(err, -EINVAL, "I2S invalid trigger setting not detected: err=%d", err);

	/* Avoid leaking queue state into subsequent tests. */
	err = i2s_trigger(dev_i2s, I2S_DIR_TX, I2S_TRIGGER_DROP);
	zassert_equal(err, 0, "I2S_TRIGGER_DROP unexpected error: %d", err);
}

ZTEST_USER(i2s_errors, test_i2s_unconfigured_access)
{
	int err;
	char tx_data[BLOCK_SIZE] = {0};
	struct i2s_config inactive_config = { .word_size = 16U,
					      .channels = 2U,
					      .format = I2S_FMT_DATA_FORMAT_I2S,
					      .frame_clk_freq = 0,
					      .block_size = BLOCK_SIZE,
					      .timeout = TIMEOUT,
					      .options = I2S_OPT_FRAME_CLK_CONTROLLER |
							 I2S_OPT_BIT_CLK_CONTROLLER,
					      .mem_slab = &tx_mem_slab };

	err = i2s_configure(dev_i2s, I2S_DIR_TX, &inactive_config);
	zassert_equal(err, 0, "I2S interface NOT_READY state transition failed. err=%d", err);

	err = i2s_buf_write(dev_i2s, tx_data, BLOCK_SIZE);
	zassert_equal(
		err, -EIO,
		"I2S attempting unconfigured interface access did not raise I/O error, err=%d",
		err);
}

ZTEST_USER(i2s_errors, test_i2s_improper_block_size_write)
{
	int err;
	char tx_data[BLOCK_SIZE] = {0};
	struct i2s_config test_config = { .word_size = 16U,
					  .channels = 2U,
					  .format = I2S_FMT_DATA_FORMAT_I2S,
					  .frame_clk_freq = FRAME_CLK_FREQ,
					  .block_size = BLOCK_SIZE,
					  .timeout = TIMEOUT,
					  .options = I2S_OPT_FRAME_CLK_CONTROLLER |
						     I2S_OPT_BIT_CLK_CONTROLLER,
					  .mem_slab = &tx_mem_slab };

	err = i2s_configure(dev_i2s, I2S_DIR_TX, &test_config);
	zassert_equal(err, 0, "Unexpected error when configuring I2S interface: %d", err);

	err = i2s_buf_write(dev_i2s, tx_data, sizeof(uint16_t) + BLOCK_SIZE);
	zassert_not_equal(
		err, 0,
		"I2S attempting write with incorrect block size did not raise error, err=%d", err);
}

static void write_to_exhausted_slab(int32_t timeout, int expected)
{
	int err;
	char tx_data[BLOCK_SIZE] = {0};
	struct i2s_config test_config = { .word_size = 16U,
					  .channels = 2U,
					  .format = I2S_FMT_DATA_FORMAT_I2S,
					  .frame_clk_freq = FRAME_CLK_FREQ,
					  .block_size = BLOCK_SIZE,
					  .timeout = timeout,
					  .options = I2S_OPT_FRAME_CLK_CONTROLLER |
						     I2S_OPT_BIT_CLK_CONTROLLER,
					  .mem_slab = &tx_mem_slab };

	err = i2s_configure(dev_i2s, I2S_DIR_TX, &test_config);
	zassert_equal(err, 0, "Unexpected error when configuring I2S interface: %d", err);

	for (int i = 0; i < NUM_TX_BLOCKS; i++) {
		err = i2s_buf_write(dev_i2s, tx_data, BLOCK_SIZE);
		zassert_equal(err, 0, "Write %d of %d failed, err=%d", i + 1, NUM_TX_BLOCKS,
			      err);
	}

	err = i2s_buf_write(dev_i2s, tx_data, BLOCK_SIZE);
	zassert_equal(err, expected, "I2S write on an exhausted slab returned %d, expected %d",
		      err, expected);

	err = i2s_trigger(dev_i2s, I2S_DIR_TX, I2S_TRIGGER_DROP);
	zassert_equal(err, 0, "Unexpected error when dropping the TX queue: %d", err);
}

ZTEST(i2s_errors, test_i2s_write_exhausted_slab_no_wait)
{
	write_to_exhausted_slab(0, -ENOMEM);
}

ZTEST_USER(i2s_errors, test_i2s_write_exhausted_slab_timeout)
{
	write_to_exhausted_slab(TIMEOUT, -EAGAIN);
}

/**
 * @brief Test the i2s_get_caps API function
 *
 * This test validates the I2S get_caps API functionality by testing both
 * successful operation and error handling scenarios.
 */
ZTEST_USER(i2s_errors, test_i2s_get_caps)
{
	int ret;
	struct audio_caps caps;

	/**
	 * Test Case 1: Normal operation - Valid parameters
	 * Expected: Function should return 0 (success) or -ENOSYS (not implemented)
	 */
	ret = i2s_get_caps(dev_i2s, &caps, I2S_DIR_RX);

	/* Handle case where driver doesn't implement get_caps */
	if (ret == -ENOSYS) {
		TC_PRINT("I2S get_caps not implemented by driver\n");
		ztest_test_skip();
		return;
	}

	/* Verify successful execution */
	zassert_equal(ret, 0, "i2s_get_caps should return 0, got %d", ret);

	/**
	 * Test Case 2: Capability value validation
	 * Verify that returned capability values are within reasonable ranges
	 */
	zassert_true(caps.min_total_channels >= 1, "min_total_channels should be >= 1, got %u",
		     caps.min_total_channels);

	zassert_true(caps.max_total_channels >= caps.min_total_channels,
		     "max_total_channels (%u) should be >= min_total_channels (%u)",
		     caps.max_total_channels, caps.min_total_channels);

	zassert_not_equal(caps.supported_sample_rates, 0, "supported_sample_rates should not be 0");

	zassert_not_equal(caps.supported_bit_widths, 0, "supported_bit_widths should not be 0");

	zassert_true(caps.min_num_buffers >= 1, "min_num_buffers should be >= 1, got %u",
		     caps.min_num_buffers);

	zassert_true(caps.max_frame_interval >= caps.min_frame_interval,
		     "max_frame_interval (%u) should be >= min_frame_interval (%u)",
		     caps.max_frame_interval, caps.min_frame_interval);

	/**
	 * Test Case 3: Error handling - NULL caps pointer
	 * Expected: Function should return -EINVAL for invalid parameter
	 */
	ret = i2s_get_caps(dev_i2s, NULL, I2S_DIR_RX);
	zassert_equal(ret, -EINVAL,
		      "i2s_get_caps should return -EINVAL for NULL caps pointer, got %d", ret);
}

/**
 * @brief Verify that RX can start with only the reported minimum number of buffers
 *
 * All but caps.min_num_buffers blocks of the RX slab are reserved before the
 * START trigger, so a driver that under-reports its RX buffer requirement
 * fails to start. Runs in kernel mode because k_mem_slab_alloc() is not a
 * system call.
 */
ZTEST(i2s_errors, test_i2s_get_caps_rx_min_num_buffers)
{
	void *reserved[NUM_RX_BLOCKS];
	uint32_t num_reserved = 0U;
	struct audio_caps caps;
	int ret;

	ret = i2s_get_caps(dev_i2s_rx, &caps, I2S_DIR_RX);
	if (ret == -ENOSYS) {
		ztest_test_skip();
		return;
	}
	zassert_equal(ret, 0, "i2s_get_caps failed: %d", ret);

	if (caps.min_num_buffers > NUM_RX_BLOCKS) {
		TC_PRINT("RX min_num_buffers %u exceeds test slab size %u\n",
			 caps.min_num_buffers, NUM_RX_BLOCKS);
		ztest_test_skip();
		return;
	}

	while (k_mem_slab_num_free_get(&rx_mem_slab) > caps.min_num_buffers) {
		ret = k_mem_slab_alloc(&rx_mem_slab, &reserved[num_reserved], K_NO_WAIT);
		zassert_equal(ret, 0, "Failed to reserve RX slab block: %d", ret);
		num_reserved++;
	}

	ret = i2s_trigger(dev_i2s_rx, I2S_DIR_RX, I2S_TRIGGER_START);

	/* Release the stream and the reserved blocks before checking the result */
	if (ret == 0) {
		(void)i2s_trigger(dev_i2s_rx, I2S_DIR_RX, I2S_TRIGGER_DROP);
	}
	for (uint32_t i = 0U; i < num_reserved; i++) {
		k_mem_slab_free(&rx_mem_slab, reserved[i]);
	}

	zassert_equal(ret, 0, "RX START failed with the reported min_num_buffers (%u): %d",
		      caps.min_num_buffers, ret);
}

/**
 * @brief Verify that TX can start after queueing the reported minimum number of buffers
 */
ZTEST_USER(i2s_errors, test_i2s_get_caps_tx_min_num_buffers)
{
	char tx_data[BLOCK_SIZE] = {0};
	struct audio_caps caps;
	int ret;

	ret = i2s_get_caps(dev_i2s_tx, &caps, I2S_DIR_TX);
	if (ret == -ENOSYS) {
		ztest_test_skip();
		return;
	}
	zassert_equal(ret, 0, "i2s_get_caps failed: %d", ret);

	if (caps.min_num_buffers > NUM_TX_BLOCKS) {
		TC_PRINT("TX min_num_buffers %u exceeds test slab size %u\n",
			 caps.min_num_buffers, NUM_TX_BLOCKS);
		ztest_test_skip();
		return;
	}

	for (uint32_t i = 0U; i < caps.min_num_buffers; i++) {
		ret = i2s_buf_write(dev_i2s_tx, tx_data, BLOCK_SIZE);
		zassert_equal(ret, 0, "TX write %u failed: %d", i, ret);
	}

	ret = i2s_trigger(dev_i2s_tx, I2S_DIR_TX, I2S_TRIGGER_START);
	if (ret == 0) {
		(void)i2s_trigger(dev_i2s_tx, I2S_DIR_TX, I2S_TRIGGER_DROP);
	}

	zassert_equal(ret, 0, "TX START failed with the reported min_num_buffers (%u): %d",
		      caps.min_num_buffers, ret);
}
```

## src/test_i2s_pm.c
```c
/*
 * SPDX-FileCopyrightText: Copyright (c) 2026 Espressif Systems (Shanghai) CO LTD
 * SPDX-License-Identifier: Apache-2.0
 */

#include <zephyr/kernel.h>
#include <zephyr/ztest.h>
#include <zephyr/drivers/i2s.h>
#include <zephyr/pm/pm.h>
#include "i2s_api_test.h"

static atomic_t standby_entries;

static void pm_state_entry(enum pm_state state)
{
	if (state == PM_STATE_STANDBY) {
		atomic_inc(&standby_entries);
	}
}

static struct pm_notifier pm_light_sleep_notifier = {
	.state_entry = pm_state_entry,
};

/* Stay idle and check that the system entered light sleep. */
static void check_light_sleep(void)
{
	atomic_clear(&standby_entries);
	k_sleep(K_MSEC(100));
	zassert_true(atomic_get(&standby_entries) > 0,
		     "System stayed active during the idle window");
}

static int run_i2s_loopback_once(void)
{
	int ret;

	ret = tx_block_write(dev_i2s, 0, 0);
	if (ret != TC_PASS) {
		return ret;
	}
	ret = tx_block_write(dev_i2s, 1, 0);
	if (ret != TC_PASS) {
		return ret;
	}

	ret = i2s_trigger(dev_i2s, I2S_DIR_BOTH, I2S_TRIGGER_START);
	zassert_equal(ret, 0, "RX/TX START failed");

	ret = rx_block_read(dev_i2s, 0);
	if (ret != TC_PASS) {
		return ret;
	}

	ret = tx_block_write(dev_i2s, 2, 0);
	if (ret != TC_PASS) {
		return ret;
	}

	ret = i2s_trigger(dev_i2s, I2S_DIR_BOTH, I2S_TRIGGER_DRAIN);
	zassert_equal(ret, 0, "RX/TX DRAIN failed");

	ret = rx_block_read(dev_i2s, 1);
	if (ret != TC_PASS) {
		return ret;
	}

	return rx_block_read(dev_i2s, 2);
}

static void *pm_setup(void)
{
	k_thread_access_grant(k_current_get(), &rx_mem_slab, &tx_mem_slab);
	k_object_access_grant(dev_i2s_rx, k_current_get());
	k_object_access_grant(dev_i2s_tx, k_current_get());

	return NULL;
}

static void pm_before(void *fixture)
{
	ARG_UNUSED(fixture);

	int ret;

	zassert_not_null(dev_i2s, "TX/RX device not found");
	zassert_true(device_is_ready(dev_i2s), "device %s is not ready",
		     dev_i2s->name);

	i2s_test_recover(dev_i2s);

	ret = configure_stream(dev_i2s, I2S_DIR_BOTH);
	zassert_equal(ret, TC_PASS);

	ret = i2s_trigger(dev_i2s, I2S_DIR_BOTH, I2S_TRIGGER_DROP);
	dir_both_supported = (ret == 0);

	if (IS_ENABLED(CONFIG_I2S_TEST_USE_I2S_DIR_BOTH)) {
		zassert_true(dir_both_supported,
			     "I2S_DIR_BOTH value is supposed to be supported.");
	}
}

/*
 * Configure once, then check that transfers still work after each light
 * sleep without configuring the stream again.
 */
ZTEST(i2s_pm, test_i2s_pm_light_sleep)
{
	if (!dir_both_supported) {
		TC_PRINT("I2S_DIR_BOTH value is not supported.\n");
		ztest_test_skip();
		return;
	}

	pm_notifier_register(&pm_light_sleep_notifier);

	for (int cycle = 0; cycle < 2; cycle++) {
		check_light_sleep();
		zassert_equal(run_i2s_loopback_once(), TC_PASS);
	}

	pm_notifier_unregister(&pm_light_sleep_notifier);
}

ZTEST_SUITE(i2s_pm, NULL, pm_setup, pm_before, NULL, NULL);
```
